# TC80_VXX register map
Vendor: Geneal MCU Ltd.; Series: ARMCM0; File version: 1.2
ARM 32-bit Cortex-M0 Microcontroller based device, CPU clock up to 32MHz, etc.
CPU: CM0 r0p0, little endian, no MPU, no FPU, 2 interrupt priority bits
Registers are 32-bit, read-write, reset 0x0 unless marked. A register's access mark holds for its fields unless they carry their own. Offsets are from the block's base; lines under a group give offsets from that group; [hi:lo] are bit positions; {n}, {i} and the like mark numbered series; 'fields as' and 'values as' point back to an identical list; <NAME> marks a mode.

## Memory map
0x40001000 SCU size 0x400 — System configuration unit
0x40008000 FLASH size 0x400
0x49000000 TIM0 size 0x400 — 16 bits Timer / Counter
0x49000400 TIM1 size 0x400 — 16 bits Timer / Counter
0x49000800 TIM2 size 0x400 — 16 bits Timer / Counter
0x49001000 GPIO0 size 0x400 — General-purpose I/Os
0x49001400 GPIO1 size 0x400 — General-purpose I/Os
0x49001800 GPIO2 size 0x400 — General-purpose I/Os
0x49001C00 GPIO3 size 0x400 — General-purpose I/Os
0x49002000 UART size 0x400 — Universal asynchronous receiver transmitter
0x49005000 I2C0 size 0x400 — Inter-integrated circuit
0x49005400 I2C1 size 0x400 — Inter-integrated circuit
0x49006000 PLU size 0x400 — Program logic unit
0x49007000 ADC size 0x400 — Analog-to-digital converter
0x49007400 DAC0 size 0x400 — Digital-to-analog converter
0x49007800 DAC1 size 0x400 — Digital-to-analog converter
0x49009000 IWDT size 0x400 — Independent watchdog
0x4900B000 EXTI size 0x400 — External interrupt/event controller

## Interrupts
0 UART — UART interrupt
1 ADC — ADC interrupt
2 FLASH — Flash global interrupt
3 TIM0 — Timer0 interrupt
4 TIM1 — Timer1 interrupt
5 TIM2 — Timer2 interrupt
{n+6} EXTI{n} (EXTI) (n=0..7) — EXTI line{n} interrupt
14 PVD (EXTI) — PVD interrupt
15 IWDT — IWDT interrupt
16 I2C0 — I2C0 interrupt
17 I2C1 — I2C1 interrupt
18 PLU — PLU interrupt
19 DAC0 — DAC0 interrupt
20 DAC1 — DAC1 interrupt

## UART — Universal asynchronous receiver transmitter
Base 0x49002000
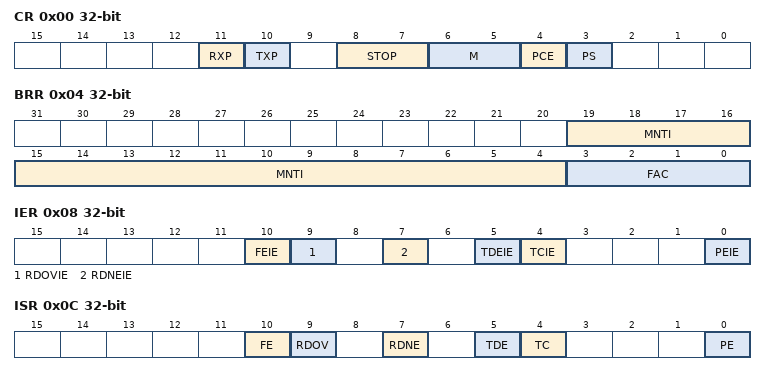
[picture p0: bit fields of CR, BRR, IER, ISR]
0x00 CR — Control register
  [11] RXP — Rx input polarity
    0=NRZ (High level as idle status); 1=NRO (Low level as idle status)
  [10] TXP — Tx output polarity
    values as RXP
  [8:7] STOP — Stop length
    0=1_Bits (1 stop bits); 1=2_Bits (2 stop bits)
  [6:5] M — Word length
    0=7_Bits (1 start bit, 7 data bits, n stop bits); 1=8_Bits (1 start bit, 8 data bits, n stop bits); 2=9_Bits (1 start bit, 9 data bits, n stop bits)
  [4] PCE — Parity control enable
    0=Diable (Parity disabled); 1=Enable (Parity enabled)
  [3] PS — Parity selection
    0=Even_Parity (Select even parity); 1=Odd_Parity (Select odd parity)
0x04 BRR — Baud rate register
  [19:4] MNTI — Mantissa value
  [3:0] FAC — Fraction value
0x08 IER — Interrupt enable register
  [10] FEIE — Flame error interrupt enable
    0=Disable (Flame error interrupt disabled); 1=Enable (Flame error interrupt enabled)
  [9] RDOVIE — Recerive data overflow interrupt enable
    0=Disable (Recerive data overflow interrupt disabled); 1=Enable (Recerive data overflow interrupt enabled)
  [7] RDNEIE — Reverive data register not empty interrupt enable
    0=Disable (Reverive data register not empty interrupt disabled); 1=Enable (Reverive data register not empty interrupt enabled)
  [5] TDEIE — Transmit data register empty interrupt enable
    0=Disable (Tansmit data register empty interrupt disabled); 1=Enable (Tansmit data register empty interrupt enabled)
  [4] TCIE — Transfer complete interrupt enable
    0=Disable (Transfer complete interrupt disabled); 1=Enable (Transfer complete interrupt enabled)
  [0] PEIE — Parity error interrupt enable
    0=Disable (Parity error interrupt disabled); 1=Enable (Parity error interrupt enabled)
0x0C ISR — Interrupt and status register
  [10] FE — Frame error
    0=No_FE (Flame error interrupt has no occured); 1=FE_Occured (Flame error interrupt has occured)
  [9] RDOV — Received data overflow
    0=No_RDOV (Receive data overflow interrupt has no occured); 1=RDOV_Occured (Receive data overflow interrupt has occured)
  [7] RDNE — Receive data register not empty
    0=No_RDNE (Receive data register not empty interrupt has no occured); 1=RNDE_Occured (Receive data register not empty interrupt has occured)
  [5] TDE — Transmit data register empty
    0=No_TDE (Transmit data register empty interrupt has no occured); 1=TDE_Occured (Transmit data register empty interrupt has occured)
  [4] TC — Transmission complete
    0=No_TC (Transmission complete interrupt has no occured); 1=TC_Occured (Transmission complete interrupt has occured)
  [0] PE — Parity error
    0=No_PE (Parity error interrupt has no occured); 1=PE_Occured (Parity error interrupt has occured)
0x10 TDR — Transmit data register
0x14 RDR — Receive data register
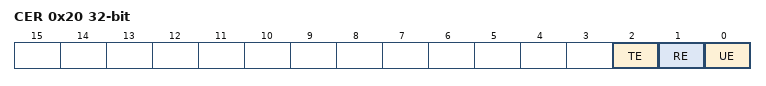
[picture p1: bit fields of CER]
0x20 CER — Uart control enable register
  [2] TE — Transmitter enable
    0=Disable (UART transmitter is disabled); 1=Enable (UART transmitter is enabled)
  [1] RE — Receiver enable
    0=Disable (UART receiver is disabled); 1=Enable (UART receiver is enabled)
  [0] UE — UART enable
    0=Disable (UART is disabled); 1=Enable (UART is enabled)

## Licence text in the file
THIS SOFTWARE IS PROVIDED "AS IS". NO WARRANTIES, WHETHER EXPRESS, IMPLIED. OR STATUTORY, INCLUDING, BUT NOT LIMITED TO, IMPLIED WARRANTIES OF. MERCHANTABILITY AND FITNESS FOR A PARTICULAR PURPOSE APPLY TO THIS SOFTWARE. ARM SHALL NOT, IN ANY CIRCUMSTANCES, BE LIABLE FOR SPECIAL, INCIDENTAL, OR. CONSEQUENTIAL DAMAGES, FOR ANY REASON WHATSOEVER.

## Notices in the file
Copyright (C) 2012-2014 ARM Limited. All rights reserved.
Purpose: System Viewer Description (SVD) Example (Schema Version 1.1)
This is a description of a none-existent and incomplete device
for demonstration purposes only.
Redistribution and use in source and binary forms, with or without
modification, are permitted provided that the following conditions are met:
- Redistributions of source code must retain the above copyright
notice, this list of conditions and the following disclaimer.
- Redistributions in binary form must reproduce the above copyright
notice, this list of conditions and the following disclaimer in the
documentation and/or other materials provided with the distribution.
- Neither the name of ARM nor the names of its contributors may be used
to endorse or promote products derived from this software without
specific prior written permission.
THIS SOFTWARE IS PROVIDED BY THE COPYRIGHT HOLDERS AND CONTRIBUTORS "AS IS"
AND ANY EXPRESS OR IMPLIED WARRANTIES, INCLUDING, BUT NOT LIMITED TO, THE
ARE DISCLAIMED. IN NO EVENT SHALL COPYRIGHT HOLDERS AND CONTRIBUTORS BE
LIABLE FOR ANY DIRECT, INDIRECT, INCIDENTAL, SPECIAL, EXEMPLARY, OR
CONSEQUENTIAL DAMAGES (INCLUDING, BUT NOT LIMITED TO, PROCUREMENT OF
SUBSTITUTE GOODS OR SERVICES; LOSS OF USE, DATA, OR PROFITS; OR BUSINESS
INTERRUPTION) HOWEVER CAUSED AND ON ANY THEORY OF LIABILITY, WHETHER IN
CONTRACT, STRICT LIABILITY, OR TORT (INCLUDING NEGLIGENCE OR OTHERWISE)
ARISING IN ANY WAY OUT OF THE USE OF THIS SOFTWARE, EVEN IF ADVISED OF THE
POSSIBILITY OF SUCH DAMAGE.
